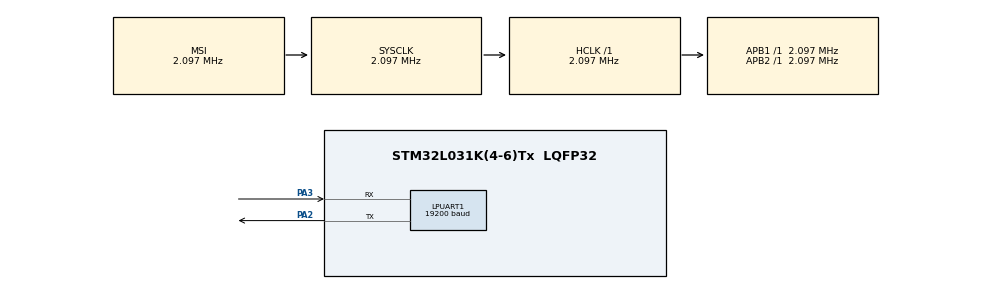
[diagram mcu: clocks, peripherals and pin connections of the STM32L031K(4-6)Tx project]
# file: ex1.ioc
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LPUART1.BaudRate=19200
LPUART1.WordLength=UART_WORDLENGTH_8B
Mcu.Family=STM32L0
Mcu.Name=STM32L031K(4-6)Tx
Mcu.Package=LQFP32
NVIC.LPUART1_IRQn=true\:0\:0\:false\:false\:true\:true\:true\:true
PA2.Mode=Asynchronous
PA2.Signal=LPUART1_TX
PA3.Mode=Asynchronous
PA3.Signal=LPUART1_RX
ProjectManager.HeapSize=0x200
ProjectManager.StackSize=0x400
ProjectManager.TargetToolchain=STM32CubeIDE
RCC.AHBFreq_Value=2097000
RCC.APB1Freq_Value=2097000
RCC.APB1TimFreq_Value=2097000
RCC.APB2Freq_Value=2097000
RCC.APB2TimFreq_Value=2097000
RCC.HSE_VALUE=8000000
RCC.HSI16_VALUE=16000000
RCC.HSI_VALUE=16000000
RCC.LSE_VALUE=32768
RCC.MSI_VALUE=2097000
RCC.SYSCLKFreq_VALUE=2097000
RCC.VCOOutputFreq_Value=48000000
board=custom

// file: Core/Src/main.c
/* USER CODE BEGIN Header */
/**
  ******************************************************************************
  * @file           : main.c
  * @brief          : Main program body
  ******************************************************************************
  * @attention
  *
  * Copyright (c) 2025 STMicroelectronics.
  * All rights reserved.
  *
  * This software is licensed under terms that can be found in the LICENSE file
  * in the root directory of this software component.
  * If no LICENSE file comes with this software, it is provided AS-IS.
  *
  ******************************************************************************
  */
/* USER CODE END Header */
#include "main.h"

/* USER CODE BEGIN PM */
#define RX_BUFFER_SIZE 16
/* USER CODE END PM */

UART_HandleTypeDef hlpuart1;

/* USER CODE BEGIN PV */

volatile uint8_t *gp_uart1_tx_address;
volatile uint16_t g_uart1_tx_count;
volatile uint8_t *gp_uart1_rx_address;
volatile uint16_t g_uart1_rx_count;
volatile uint16_t g_uart1_rx_length;

uint8_t rxbuffer[RX_BUFFER_SIZE];

/* USER CODE END PV */

void SystemClock_Config(void);
static void MX_GPIO_Init(void);
static void MX_LPUART1_UART_Init(void);

/* USER CODE BEGIN 0 */

void UART_Stop(void);
HAL_StatusTypeDef UART_Send(uint8_t *tx_buf, uint16_t tx_num);
HAL_StatusTypeDef UART_Receive(uint8_t *rx_buf, uint16_t rx_num);
void DelayWithSleep(uint32_t iterations);

/* USER CODE END 0 */

int main(void)
{

  /* MCU Configuration--------------------------------------------------------*/

  /* Reset of all peripherals, Initializes the Flash interface and the Systick. */
  HAL_Init();

  /* Configure the system clock */
  SystemClock_Config();

  /* Initialize all configured peripherals */
  MX_GPIO_Init();
  MX_LPUART1_UART_Init();
  /* USER CODE BEGIN 2 */
  DelayWithSleep(10);
  /* USER CODE END 2 */

  /* Infinite loop */
  /* USER CODE BEGIN WHILE */

  UART_Receive(rxbuffer, RX_BUFFER_SIZE);

  while (1)
  {
    /* USER CODE END WHILE */

  }
}

void SystemClock_Config(void)
{
  RCC_OscInitTypeDef RCC_OscInitStruct = {0};
  RCC_ClkInitTypeDef RCC_ClkInitStruct = {0};
  RCC_PeriphCLKInitTypeDef PeriphClkInit = {0};

  /** Configure the main internal regulator output voltage
  */
  __HAL_PWR_VOLTAGESCALING_CONFIG(PWR_REGULATOR_VOLTAGE_SCALE1);

  /** Initializes the RCC Oscillators according to the specified parameters
  * in the RCC_OscInitTypeDef structure.
  */
  RCC_OscInitStruct.OscillatorType = RCC_OSCILLATORTYPE_MSI;
  RCC_OscInitStruct.MSIState = RCC_MSI_ON;
  RCC_OscInitStruct.MSICalibrationValue = 0;
  RCC_OscInitStruct.MSIClockRange = RCC_MSIRANGE_5;
  RCC_OscInitStruct.PLL.PLLState = RCC_PLL_NONE;
  if (HAL_RCC_OscConfig(&RCC_OscInitStruct) != HAL_OK)
  {
    Error_Handler();
  }

  /** Initializes the CPU, AHB and APB buses clocks
  */
  RCC_ClkInitStruct.ClockType = RCC_CLOCKTYPE_HCLK|RCC_CLOCKTYPE_SYSCLK
                              |RCC_CLOCKTYPE_PCLK1|RCC_CLOCKTYPE_PCLK2;
  RCC_ClkInitStruct.SYSCLKSource = RCC_SYSCLKSOURCE_MSI;
  RCC_ClkInitStruct.AHBCLKDivider = RCC_SYSCLK_DIV1;
  RCC_ClkInitStruct.APB1CLKDivider = RCC_HCLK_DIV1;
  RCC_ClkInitStruct.APB2CLKDivider = RCC_HCLK_DIV1;

  if (HAL_RCC_ClockConfig(&RCC_ClkInitStruct, FLASH_LATENCY_0) != HAL_OK)
  {
    Error_Handler();
  }
  PeriphClkInit.PeriphClockSelection = RCC_PERIPHCLK_LPUART1;
  PeriphClkInit.Lpuart1ClockSelection = RCC_LPUART1CLKSOURCE_PCLK1;
  if (HAL_RCCEx_PeriphCLKConfig(&PeriphClkInit) != HAL_OK)
  {
    Error_Handler();
  }
}

static void MX_LPUART1_UART_Init(void)
{

  hlpuart1.Instance = LPUART1;
  hlpuart1.Init.BaudRate = 19200;
  hlpuart1.Init.WordLength = UART_WORDLENGTH_8B;
  hlpuart1.Init.StopBits = UART_STOPBITS_1;
  hlpuart1.Init.Parity = UART_PARITY_NONE;
  hlpuart1.Init.Mode = UART_MODE_TX_RX;
  hlpuart1.Init.HwFlowCtl = UART_HWCONTROL_NONE;
  hlpuart1.Init.OneBitSampling = UART_ONE_BIT_SAMPLE_DISABLE;
  hlpuart1.AdvancedInit.AdvFeatureInit = UART_ADVFEATURE_NO_INIT;
  if (HAL_UART_Init(&hlpuart1) != HAL_OK)
  {
    Error_Handler();
  }

}

static void MX_GPIO_Init(void)
{

  /* GPIO Ports Clock Enable */
  __HAL_RCC_GPIOA_CLK_ENABLE();

}

/* USER CODE BEGIN 4 */

void UART_Stop(void)
{
    HAL_UART_Abort_IT(&hlpuart1);
}

HAL_StatusTypeDef UART_Send(uint8_t *tx_buf, uint16_t tx_num)
{
    if (tx_num < 1)
        return HAL_ERROR;

    gp_uart1_tx_address = tx_buf;
    g_uart1_tx_count = tx_num;

    /* Initiate transmission in IT (interrupt) mode.
       The HAL library will call HAL_UART_TxCpltCallback when done. */
    return HAL_UART_Transmit_IT(&hlpuart1, tx_buf, tx_num);
}

HAL_StatusTypeDef UART_Receive(uint8_t *rx_buf, uint16_t rx_num)
{
    if (rx_num < 1)
        return HAL_ERROR;

    gp_uart1_rx_address = rx_buf;
    g_uart1_rx_count = 0;
    g_uart1_rx_length = rx_num;

    /* Start reception in IT mode.
       The HAL library will call HAL_UART_RxCpltCallback when done. */
    return HAL_UART_Receive_IT(&hlpuart1, rx_buf, rx_num);
}

void DelayWithSleep(uint32_t iterations)
{
	while(iterations--)
	{
		// Optionally restart the watchdog here if using one:
		// HAL_IWDG_Refresh(&hiwdg);

	    // Enter Sleep mode, waiting for any interrupt.
	       HAL_PWR_EnterSLEEPMode(PWR_MAINREGULATOR_ON, PWR_SLEEPENTRY_WFI);

	    // Execution resumes here after an interrupt wakes the MCU.
	}
}

/* USER CODE END 4 */

void Error_Handler(void)
{
  __disable_irq();
  while (1)
  {
  }
}
